# MKL34Z4 register map
Vendor: Freescale Semiconductor, Inc.; File version: 1.6
CPU: CM0PLUS r0p0, little endian, no MPU, no FPU, 0x2 interrupt priority bits, 0x0 interrupts
Registers are 32-bit, read-write, reset 0x0 unless marked. A register's access mark holds for its fields unless they carry their own. Offsets are from the block's base; [hi:lo] are bit positions; {n}, {i} and the like mark numbered series.

## LPTMR0 — Low Power Timer
Base 0x40040000; register names take the prefix LPTMR0_
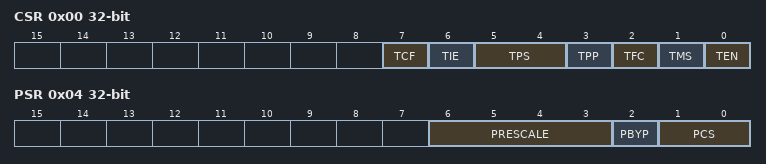
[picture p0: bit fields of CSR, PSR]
0x00 CSR — Low Power Timer Control Status Register
  [7] TCF — Timer Compare Flag
    0=The value of CNR is not equal to CMR and increments; 1=The value of CNR is equal to CMR and increments
  [6] TIE — Timer Interrupt Enable
    0=Timer interrupt disabled; 1=Timer interrupt enabled
  [5:4] TPS — Timer Pin Select
    {v}=Pulse counter input {v} is selected (v=0..3)
  [3] TPP — Timer Pin Polarity
    0=Pulse Counter input source is active-high, and the CNR will increment on the rising-edge; 1=Pulse Counter input source is active-low, and the CNR will increment on the falling-edge
  [2] TFC — Timer Free-Running Counter
    0=CNR is reset whenever TCF is set; 1=CNR is reset on overflow
  [1] TMS — Timer Mode Select
    0=Time Counter mode; 1=Pulse Counter mode
  [0] TEN — Timer Enable
    0=LPTMR is disabled and internal logic is reset; 1=LPTMR is enabled
0x04 PSR — Low Power Timer Prescale Register
  [6:3] PRESCALE — Prescale Value
    0=Prescaler divides the prescaler clock by 2; glitch filter does not support this configuration; 1=Prescaler divides the prescaler clock by 4; glitch filter recognizes change on input pin after 2 rising clock edges; 2=Prescaler divides the prescaler clock by 8; glitch filter recognizes change on input pin after 4 rising clock edges; 3=Prescaler divides the prescaler clock by 16; glitch filter recognizes change on input pin after 8 rising clock edges; 4=Prescaler divides the prescaler clock by 32; glitch filter recognizes change on input pin after 16 rising clock edges; 5=Prescaler divides the prescaler clock by 64; glitch filter recognizes change on input pin after 32 rising clock edges; 6=Prescaler divides the prescaler clock by 128; glitch filter recognizes change on input pin after 64 rising clock edges; 7=Prescaler divides the prescaler clock by 256; glitch filter recognizes change on input pin after 128 rising clock edges; 8=Prescaler divides the prescaler clock by 512; glitch filter recognizes change on input pin after 256 rising clock edges; 9=Prescaler divides the prescaler clock by 1024; glitch filter recognizes change on input pin after 512 rising clock edges; 10=Prescaler divides the prescaler clock by 2048; glitch filter recognizes change on input pin after 1024 rising clock edges; 11=Prescaler divides the prescaler clock by 4096; glitch filter recognizes change on input pin after 2048 rising clock edges; 12=Prescaler divides the prescaler clock by 8192; glitch filter recognizes change on input pin after 4096 rising clock edges; 13=Prescaler divides the prescaler clock by 16,384; glitch filter recognizes change on input pin after 8192 rising clock edges; 14=Prescaler divides the prescaler clock by 32,768; glitch filter recognizes change on input pin after 16,384 rising clock edges; 15=Prescaler divides the prescaler clock by 65,536; glitch filter recognizes change on input pin after 32,768 rising clock edges
  [2] PBYP — Prescaler Bypass
    0=Prescaler/glitch filter is enabled; 1=Prescaler/glitch filter is bypassed
  [1:0] PCS — Prescaler Clock Select
    {v}=Prescaler/glitch filter clock {v} selected (v=0..3)
0x08 CMR — Low Power Timer Compare Register
  [15:0] COMPARE — Compare Value
0x0C CNR — Low Power Timer Counter Register
  [15:0] COUNTER — Counter Value

## OSC0 — Oscillator
Base 0x40065000; register names take the prefix OSC0_
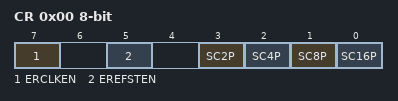
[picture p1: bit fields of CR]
0x00 CR 8-bit — OSC Control Register
  [7] ERCLKEN — External Reference Enable
    0=External reference clock is inactive; 1=External reference clock is enabled
  [5] EREFSTEN — External Reference Stop Enable
    0=External reference clock is disabled in Stop mode; 1=External reference clock stays enabled in Stop mode if ERCLKEN is set before entering Stop mode
  [3] SC2P — Oscillator 2 pF Capacitor Load Configure
    0=Disable the selection; 1=Add 2 pF capacitor to the oscillator load
  [2] SC4P — Oscillator 4 pF Capacitor Load Configure
    0=Disable the selection; 1=Add 4 pF capacitor to the oscillator load
  [1] SC8P — Oscillator 8 pF Capacitor Load Configure
    0=Disable the selection; 1=Add 8 pF capacitor to the oscillator load
  [0] SC16P — Oscillator 16 pF Capacitor Load Configure
    0=Disable the selection; 1=Add 16 pF capacitor to the oscillator load
